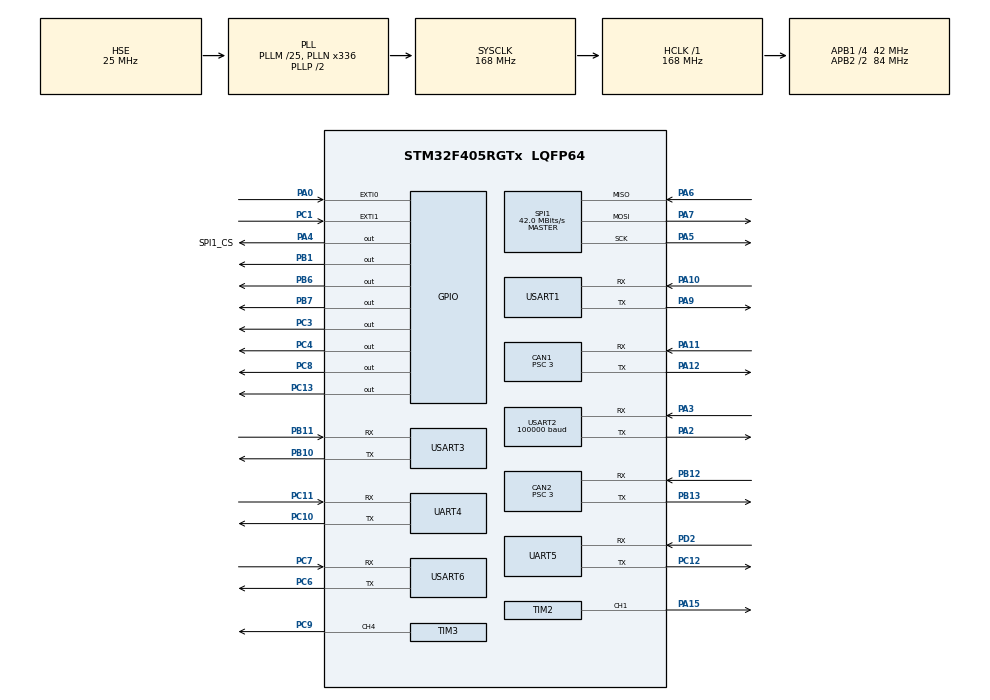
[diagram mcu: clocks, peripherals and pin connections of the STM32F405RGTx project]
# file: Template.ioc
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CAN1.ABOM=ENABLE
CAN1.BS1=CAN_BS1_9TQ
CAN1.BS2=CAN_BS2_4TQ
CAN1.CalculateBaudRate=1000000
CAN1.CalculateTimeBit=1000
CAN1.CalculateTimeQuantum=71.42857142857143
CAN1.NART=ENABLE
CAN1.Prescaler=3
CAN2.ABOM=ENABLE
CAN2.BS1=CAN_BS1_9TQ
CAN2.BS2=CAN_BS2_4TQ
CAN2.CalculateBaudRate=1000000
CAN2.CalculateTimeBit=1000
CAN2.CalculateTimeQuantum=71.42857142857143
CAN2.NART=ENABLE
CAN2.Prescaler=3
Dma.Request0=UART4_RX
Dma.Request1=UART4_TX
Dma.Request10=USART2_RX
Dma.Request2=UART5_RX
Dma.Request3=UART5_TX
Dma.Request4=USART1_RX
Dma.Request5=USART1_TX
Dma.Request6=USART3_RX
Dma.Request7=USART3_TX
Dma.Request8=USART6_RX
Dma.Request9=USART6_TX
Dma.UART4_RX.0.Direction=DMA_PERIPH_TO_MEMORY
Dma.UART4_RX.0.FIFOMode=DMA_FIFOMODE_DISABLE
Dma.UART4_RX.0.Instance=DMA1_Stream2
Dma.UART4_RX.0.MemDataAlignment=DMA_MDATAALIGN_BYTE
Dma.UART4_RX.0.MemInc=DMA_MINC_ENABLE
Dma.UART4_RX.0.Mode=DMA_NORMAL
Dma.UART4_RX.0.PeriphDataAlignment=DMA_PDATAALIGN_BYTE
Dma.UART4_RX.0.PeriphInc=DMA_PINC_DISABLE
Dma.UART4_RX.0.Priority=DMA_PRIORITY_LOW
Dma.UART4_TX.1.Direction=DMA_MEMORY_TO_PERIPH
Dma.UART4_TX.1.FIFOMode=DMA_FIFOMODE_DISABLE
Dma.UART4_TX.1.Instance=DMA1_Stream4
Dma.UART4_TX.1.MemDataAlignment=DMA_MDATAALIGN_BYTE
Dma.UART4_TX.1.MemInc=DMA_MINC_ENABLE
Dma.UART4_TX.1.Mode=DMA_NORMAL
Dma.UART4_TX.1.PeriphDataAlignment=DMA_PDATAALIGN_BYTE
Dma.UART4_TX.1.PeriphInc=DMA_PINC_DISABLE
Dma.UART4_TX.1.Priority=DMA_PRIORITY_LOW
Dma.UART5_RX.2.Direction=DMA_PERIPH_TO_MEMORY
Dma.UART5_RX.2.FIFOMode=DMA_FIFOMODE_DISABLE
Dma.UART5_RX.2.Instance=DMA1_Stream0
Dma.UART5_RX.2.MemDataAlignment=DMA_MDATAALIGN_BYTE
Dma.UART5_RX.2.MemInc=DMA_MINC_ENABLE
Dma.UART5_RX.2.Mode=DMA_NORMAL
Dma.UART5_RX.2.PeriphDataAlignment=DMA_PDATAALIGN_BYTE
Dma.UART5_RX.2.PeriphInc=DMA_PINC_DISABLE
Dma.UART5_RX.2.Priority=DMA_PRIORITY_LOW
Dma.UART5_TX.3.Direction=DMA_MEMORY_TO_PERIPH
Dma.UART5_TX.3.FIFOMode=DMA_FIFOMODE_DISABLE
Dma.UART5_TX.3.Instance=DMA1_Stream7
Dma.UART5_TX.3.MemDataAlignment=DMA_MDATAALIGN_BYTE
Dma.UART5_TX.3.MemInc=DMA_MINC_ENABLE
Dma.UART5_TX.3.Mode=DMA_NORMAL
Dma.UART5_TX.3.PeriphDataAlignment=DMA_PDATAALIGN_BYTE
Dma.UART5_TX.3.PeriphInc=DMA_PINC_DISABLE
Dma.UART5_TX.3.Priority=DMA_PRIORITY_LOW
Dma.USART1_RX.4.Direction=DMA_PERIPH_TO_MEMORY
Dma.USART1_RX.4.FIFOMode=DMA_FIFOMODE_DISABLE
Dma.USART1_RX.4.Instance=DMA2_Stream2
Dma.USART1_RX.4.MemDataAlignment=DMA_MDATAALIGN_BYTE
Dma.USART1_RX.4.MemInc=DMA_MINC_ENABLE
Dma.USART1_RX.4.Mode=DMA_NORMAL
Dma.USART1_RX.4.PeriphDataAlignment=DMA_PDATAALIGN_BYTE
Dma.USART1_RX.4.PeriphInc=DMA_PINC_DISABLE
Dma.USART1_RX.4.Priority=DMA_PRIORITY_LOW
Dma.USART1_TX.5.Direction=DMA_MEMORY_TO_PERIPH
Dma.USART1_TX.5.FIFOMode=DMA_FIFOMODE_DISABLE
Dma.USART1_TX.5.Instance=DMA2_Stream7
Dma.USART1_TX.5.MemDataAlignment=DMA_MDATAALIGN_BYTE
Dma.USART1_TX.5.MemInc=DMA_MINC_ENABLE
Dma.USART1_TX.5.Mode=DMA_NORMAL
Dma.USART1_TX.5.PeriphDataAlignment=DMA_PDATAALIGN_BYTE
Dma.USART1_TX.5.PeriphInc=DMA_PINC_DISABLE
Dma.USART1_TX.5.Priority=DMA_PRIORITY_LOW
Dma.USART2_RX.10.Direction=DMA_PERIPH_TO_MEMORY
Dma.USART2_RX.10.FIFOMode=DMA_FIFOMODE_DISABLE
Dma.USART2_RX.10.Instance=DMA1_Stream5
Dma.USART2_RX.10.MemDataAlignment=DMA_MDATAALIGN_BYTE
Dma.USART2_RX.10.MemInc=DMA_MINC_ENABLE
Dma.USART2_RX.10.Mode=DMA_NORMAL
Dma.USART2_RX.10.PeriphDataAlignment=DMA_PDATAALIGN_BYTE
Dma.USART2_RX.10.PeriphInc=DMA_PINC_DISABLE
Dma.USART2_RX.10.Priority=DMA_PRIORITY_LOW
Dma.USART3_RX.6.Direction=DMA_PERIPH_TO_MEMORY
Dma.USART3_RX.6.FIFOMode=DMA_FIFOMODE_DISABLE
Dma.USART3_RX.6.Instance=DMA1_Stream1
Dma.USART3_RX.6.MemDataAlignment=DMA_MDATAALIGN_BYTE
Dma.USART3_RX.6.MemInc=DMA_MINC_ENABLE
Dma.USART3_RX.6.Mode=DMA_NORMAL
Dma.USART3_RX.6.PeriphDataAlignment=DMA_PDATAALIGN_BYTE
Dma.USART3_RX.6.PeriphInc=DMA_PINC_DISABLE
Dma.USART3_RX.6.Priority=DMA_PRIORITY_LOW
Dma.USART3_TX.7.Direction=DMA_MEMORY_TO_PERIPH
Dma.USART3_TX.7.FIFOMode=DMA_FIFOMODE_DISABLE
Dma.USART3_TX.7.Instance=DMA1_Stream3
Dma.USART3_TX.7.MemDataAlignment=DMA_MDATAALIGN_BYTE
Dma.USART3_TX.7.MemInc=DMA_MINC_ENABLE
Dma.USART3_TX.7.Mode=DMA_NORMAL
Dma.USART3_TX.7.PeriphDataAlignment=DMA_PDATAALIGN_BYTE
Dma.USART3_TX.7.PeriphInc=DMA_PINC_DISABLE
Dma.USART3_TX.7.Priority=DMA_PRIORITY_LOW
Dma.USART6_RX.8.Direction=DMA_PERIPH_TO_MEMORY
Dma.USART6_RX.8.FIFOMode=DMA_FIFOMODE_DISABLE
Dma.USART6_RX.8.Instance=DMA2_Stream1
Dma.USART6_RX.8.MemDataAlignment=DMA_MDATAALIGN_BYTE
Dma.USART6_RX.8.MemInc=DMA_MINC_ENABLE
Dma.USART6_RX.8.Mode=DMA_NORMAL
Dma.USART6_RX.8.PeriphDataAlignment=DMA_PDATAALIGN_BYTE
Dma.USART6_RX.8.PeriphInc=DMA_PINC_DISABLE
Dma.USART6_RX.8.Priority=DMA_PRIORITY_LOW
Dma.USART6_TX.9.Direction=DMA_MEMORY_TO_PERIPH
Dma.USART6_TX.9.FIFOMode=DMA_FIFOMODE_DISABLE
Dma.USART6_TX.9.Instance=DMA2_Stream6
Dma.USART6_TX.9.MemDataAlignment=DMA_MDATAALIGN_BYTE
Dma.USART6_TX.9.MemInc=DMA_MINC_ENABLE
Dma.USART6_TX.9.Mode=DMA_NORMAL
Dma.USART6_TX.9.PeriphDataAlignment=DMA_PDATAALIGN_BYTE
Dma.USART6_TX.9.PeriphInc=DMA_PINC_DISABLE
Dma.USART6_TX.9.Priority=DMA_PRIORITY_LOW
FREERTOS.INCLUDE_vTaskDelayUntil=1
FREERTOS.Tasks01=defaultTask,0,128,StartDefaultTask,Default,NULL
Mcu.Family=STM32F4
Mcu.Name=STM32F405RGTx
Mcu.Package=LQFP64
NVIC.CAN1_RX0_IRQn=true\:5\:0\:false\:false\:true\:true\:true\:true\:true
NVIC.CAN1_RX1_IRQn=true\:5\:0\:false\:false\:true\:true\:true\:true\:true
NVIC.CAN2_RX0_IRQn=true\:5\:0\:false\:false\:true\:true\:true\:true\:true
NVIC.CAN2_RX1_IRQn=true\:5\:0\:false\:false\:true\:true\:true\:true\:true
NVIC.DMA1_Stream0_IRQn=true\:5\:0\:false\:false\:true\:true\:false\:true\:true
NVIC.DMA1_Stream1_IRQn=true\:5\:0\:false\:false\:true\:true\:false\:true\:true
NVIC.DMA1_Stream2_IRQn=true\:5\:0\:false\:false\:true\:true\:false\:true\:true
NVIC.DMA1_Stream3_IRQn=true\:5\:0\:false\:false\:true\:true\:false\:true\:true
NVIC.DMA1_Stream4_IRQn=true\:5\:0\:false\:false\:true\:true\:false\:true\:true
NVIC.DMA1_Stream5_IRQn=true\:5\:0\:false\:false\:true\:true\:false\:true\:true
NVIC.DMA1_Stream7_IRQn=true\:5\:0\:false\:false\:true\:true\:false\:true\:true
NVIC.DMA2_Stream1_IRQn=true\:5\:0\:false\:false\:true\:true\:false\:true\:true
NVIC.DMA2_Stream2_IRQn=true\:5\:0\:false\:false\:true\:true\:false\:true\:true
NVIC.DMA2_Stream6_IRQn=true\:5\:0\:false\:false\:true\:true\:false\:true\:true
NVIC.DMA2_Stream7_IRQn=true\:5\:0\:false\:false\:true\:true\:false\:true\:true
NVIC.EXTI0_IRQn=true\:5\:0\:false\:false\:true\:false\:true\:true\:true
NVIC.EXTI1_IRQn=true\:5\:0\:false\:false\:true\:false\:true\:true\:true
NVIC.PriorityGroup=NVIC_PRIORITYGROUP_4
NVIC.TIM4_IRQn=true\:5\:0\:false\:false\:true\:false\:true\:true\:true
NVIC.TIM7_IRQn=true\:0\:0\:false\:false\:true\:false\:false\:true\:true
NVIC.TimeBase=TIM7_IRQn
NVIC.TimeBaseIP=TIM7
NVIC.UART4_IRQn=true\:5\:0\:false\:false\:true\:true\:true\:true\:true
NVIC.UART5_IRQn=true\:5\:0\:false\:false\:true\:true\:true\:true\:true
NVIC.USART1_IRQn=true\:5\:0\:false\:false\:true\:true\:true\:true\:true
NVIC.USART2_IRQn=true\:5\:0\:false\:false\:true\:true\:true\:true\:true
NVIC.USART3_IRQn=true\:5\:0\:false\:false\:true\:true\:true\:true\:true
NVIC.USART6_IRQn=true\:5\:0\:false\:false\:true\:true\:true\:true\:true
PA0-WKUP.GPIO_PuPd=GPIO_PULLUP
PA0-WKUP.Signal=GPXTI0
PA10.Mode=Asynchronous
PA10.Signal=USART1_RX
PA11.Mode=CAN_Activate
PA11.Signal=CAN1_RX
PA12.Mode=CAN_Activate
PA12.Signal=CAN1_TX
PA13.Mode=Serial_Wire
PA13.Signal=SYS_JTMS-SWDIO
PA14.Mode=Serial_Wire
PA14.Signal=SYS_JTCK-SWCLK
PA15.Signal=S_TIM2_CH1_ETR
PA2.Mode=Asynchronous
PA2.Signal=USART2_TX
PA3.Mode=Asynchronous
PA3.Signal=USART2_RX
PA4.GPIO_Label=SPI1_CS
PA4.GPIO_Speed=GPIO_SPEED_FREQ_HIGH
PA4.Signal=GPIO_Output
PA5.Mode=Full_Duplex_Master
PA5.Signal=SPI1_SCK
PA6.Mode=Full_Duplex_Master
PA6.Signal=SPI1_MISO
PA7.Mode=Full_Duplex_Master
PA7.Signal=SPI1_MOSI
PA9.Mode=Asynchronous
PA9.Signal=USART1_TX
PB1.Signal=GPIO_Output
PB10.Mode=Asynchronous
PB10.Signal=USART3_TX
PB11.Mode=Asynchronous
PB11.Signal=USART3_RX
PB12.Mode=CAN_Activate
PB12.Signal=CAN2_RX
PB13.Mode=CAN_Activate
PB13.Signal=CAN2_TX
PB6.GPIO_ModeDefaultOutputPP=GPIO_MODE_OUTPUT_OD
PB6.GPIO_PuPd=GPIO_PULLUP
PB6.GPIO_Speed=GPIO_SPEED_FREQ_VERY_HIGH
PB6.PinState=GPIO_PIN_RESET
PB6.Signal=GPIO_Output
PB7.GPIO_ModeDefaultOutputPP=GPIO_MODE_OUTPUT_OD
PB7.GPIO_PuPd=GPIO_PULLUP
PB7.GPIO_Speed=GPIO_SPEED_FREQ_VERY_HIGH
PB7.Signal=GPIO_Output
PC1.GPIO_PuPd=GPIO_PULLUP
PC1.Signal=GPXTI1
PC10.Mode=Asynchronous
PC10.Signal=UART4_TX
PC11.Mode=Asynchronous
PC11.Signal=UART4_RX
PC12.Mode=Asynchronous
PC12.Signal=UART5_TX
PC13-ANTI_TAMP.Signal=GPIO_Output
PC3.GPIO_PuPd=GPIO_PULLUP
PC3.Signal=GPIO_Output
PC4.Signal=GPIO_Output
PC6.Mode=Asynchronous
PC6.Signal=USART6_TX
PC7.Mode=Asynchronous
PC7.Signal=USART6_RX
PC8.Signal=GPIO_Output
PC9.Signal=S_TIM3_CH4
PD2.Mode=Asynchronous
PD2.Signal=UART5_RX
PH0-OSC_IN.Mode=HSE-External-Oscillator
PH0-OSC_IN.Signal=RCC_OSC_IN
PH1-OSC_OUT.Mode=HSE-External-Oscillator
PH1-OSC_OUT.Signal=RCC_OSC_OUT
ProjectManager.HeapSize=0x200
ProjectManager.StackSize=0x400
ProjectManager.TargetToolchain=MDK-ARM V5.27
RCC.48MHZClocksFreq_Value=84000000
RCC.AHBFreq_Value=168000000
RCC.APB1CLKDivider=RCC_HCLK_DIV4
RCC.APB1Freq_Value=42000000
RCC.APB1TimFreq_Value=84000000
RCC.APB2CLKDivider=RCC_HCLK_DIV2
RCC.APB2Freq_Value=84000000
RCC.APB2TimFreq_Value=168000000
RCC.CortexFreq_Value=168000000
RCC.HCLKFreq_Value=168000000
RCC.HSE_VALUE=25000000
RCC.HSI_VALUE=16000000
RCC.LSE_VALUE=32768
RCC.PLLM=25
RCC.PLLN=336
RCC.PLLSourceVirtual=RCC_PLLSOURCE_HSE
RCC.RCC_RTC_Clock_Source=RCC_RTCCLKSOURCE_LSI
RCC.RCC_RTC_Clock_SourceVirtual=RCC_RTCCLKSOURCE_LSI
RCC.SYSCLKFreq_VALUE=168000000
RCC.SYSCLKSource=RCC_SYSCLKSOURCE_PLLCLK
RCC.VCOOutputFreq_Value=336000000
SH.S_TIM2_CH1_ETR.0=TIM2_CH1,PWM Generation1 CH1
SH.S_TIM3_CH4.0=TIM3_CH4,PWM Generation4 CH4
SPI1.CalculateBaudRate=42.0 MBits/s
SPI1.Direction=SPI_DIRECTION_2LINES
SPI1.Mode=SPI_MODE_MASTER
SPI1.VirtualType=VM_MASTER
TIM2.Channel-PWM\ Generation1\ CH1=TIM_CHANNEL_1
TIM2.OCMode_PWM-PWM\ Generation1\ CH1=TIM_OCMODE_PWM2
TIM2.Period=999
TIM2.Prescaler=41
TIM3.Channel-PWM\ Generation4\ CH4=TIM_CHANNEL_4
TIM3.OCMode_PWM-PWM\ Generation4\ CH4=TIM_OCMODE_PWM2
TIM3.Period=999
TIM3.Prescaler=42
TIM4.Period=65535
TIM4.Prescaler=83
UART4.VirtualMode=Asynchronous
UART5.VirtualMode=Asynchronous
USART1.VirtualMode=VM_ASYNC
USART2.BaudRate=100000
USART2.Mode=MODE_RX
USART2.Parity=PARITY_EVEN
USART2.VirtualMode=VM_ASYNC
USART2.WordLength=WORDLENGTH_9B
USART3.VirtualMode=VM_ASYNC
USART6.VirtualMode=VM_ASYNC
VP_FREERTOS_VS_CMSIS_V1.Mode=CMSIS_V1
VP_SYS_VS_tim7.Mode=TIM7
VP_TIM2_VS_ClockSourceINT.Mode=Internal
VP_TIM3_VS_ClockSourceINT.Mode=Internal
VP_TIM4_VS_ClockSourceINT.Mode=Internal
board=custom

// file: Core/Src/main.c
/* USER CODE BEGIN Header */
/**
  ******************************************************************************
  * @file           : main.c
  * @brief          : Main program body
  ******************************************************************************
  * @attention
  *
  * <h2><center>&copy; Copyright (c) 2019 STMicroelectronics.
  * All rights reserved.</center></h2>
  *
  * This software component is licensed by ST under Ultimate Liberty license
  * SLA0044, the "License"; You may not use this file except in compliance with
  * the License. You may obtain a copy of the License at:
  *                             www.st.com/SLA0044
  *
  ******************************************************************************
  */
/* USER CODE END Header */
#include "main.h"
#include "cmsis_os.h"

/* USER CODE BEGIN Includes */
#include "app.h"
#include "SRML.h"
/* USER CODE END Includes */

CAN_HandleTypeDef hcan1;
CAN_HandleTypeDef hcan2;

SPI_HandleTypeDef hspi1;

TIM_HandleTypeDef htim2;
TIM_HandleTypeDef htim3;
TIM_HandleTypeDef htim4;

UART_HandleTypeDef huart4;
UART_HandleTypeDef huart5;
UART_HandleTypeDef huart1;
UART_HandleTypeDef huart2;
UART_HandleTypeDef huart3;
UART_HandleTypeDef huart6;
DMA_HandleTypeDef hdma_uart4_rx;
DMA_HandleTypeDef hdma_uart4_tx;
DMA_HandleTypeDef hdma_uart5_rx;
DMA_HandleTypeDef hdma_uart5_tx;
DMA_HandleTypeDef hdma_usart1_rx;
DMA_HandleTypeDef hdma_usart1_tx;
DMA_HandleTypeDef hdma_usart2_rx;
DMA_HandleTypeDef hdma_usart3_rx;
DMA_HandleTypeDef hdma_usart3_tx;
DMA_HandleTypeDef hdma_usart6_rx;
DMA_HandleTypeDef hdma_usart6_tx;

osThreadId defaultTaskHandle;

void SystemClock_Config(void);
static void MX_GPIO_Init(void);
static void MX_DMA_Init(void);
static void MX_CAN1_Init(void);
static void MX_CAN2_Init(void);
static void MX_TIM4_Init(void);
static void MX_UART4_Init(void);
static void MX_UART5_Init(void);
static void MX_USART1_UART_Init(void);
static void MX_USART2_UART_Init(void);
static void MX_USART3_UART_Init(void);
static void MX_USART6_UART_Init(void);
static void MX_SPI1_Init(void);
static void MX_TIM2_Init(void);
static void MX_TIM3_Init(void);
void StartDefaultTask(void const * argument);

int main(void)
{

  /* MCU Configuration--------------------------------------------------------*/

  /* Reset of all peripherals, Initializes the Flash interface and the Systick. */
  HAL_Init();

  /* Configure the system clock */
  SystemClock_Config();

  /* Initialize all configured peripherals */
  MX_GPIO_Init();
  MX_DMA_Init();
  MX_CAN1_Init();
  MX_CAN2_Init();
  MX_TIM4_Init();
  MX_UART4_Init();
  MX_UART5_Init();
  MX_USART1_UART_Init();
  MX_USART2_UART_Init();
  MX_USART3_UART_Init();
  MX_USART6_UART_Init();
  MX_SPI1_Init();
  MX_TIM2_Init();
  MX_TIM3_Init();
  /* USER CODE BEGIN 2 */
  System_Device_Init();
	HAL_TIM_PWM_Start(&htim2, TIM_CHANNEL_1);
	HAL_TIM_PWM_Start(&htim3, TIM_CHANNEL_4);
  /* USER CODE END 2 */

  /* Create the thread(s) */
  /* definition and creation of defaultTask */
  osThreadDef(defaultTask, StartDefaultTask, osPriorityNormal, 0, 128);
  defaultTaskHandle = osThreadCreate(osThread(defaultTask), NULL);

  /* Start scheduler */
  osKernelStart();
  /* We should never get here as control is now taken by the scheduler */
  /* Infinite loop */
  while (1)
  {

  }
}

void SystemClock_Config(void)
{
  RCC_OscInitTypeDef RCC_OscInitStruct = {0};
  RCC_ClkInitTypeDef RCC_ClkInitStruct = {0};

  /** Configure the main internal regulator output voltage
  */
  __HAL_RCC_PWR_CLK_ENABLE();
  __HAL_PWR_VOLTAGESCALING_CONFIG(PWR_REGULATOR_VOLTAGE_SCALE1);

  /** Initializes the RCC Oscillators according to the specified parameters
  * in the RCC_OscInitTypeDef structure.
  */
  RCC_OscInitStruct.OscillatorType = RCC_OSCILLATORTYPE_HSE;
  RCC_OscInitStruct.HSEState = RCC_HSE_ON;
  RCC_OscInitStruct.PLL.PLLState = RCC_PLL_ON;
  RCC_OscInitStruct.PLL.PLLSource = RCC_PLLSOURCE_HSE;
  RCC_OscInitStruct.PLL.PLLM = 25;
  RCC_OscInitStruct.PLL.PLLN = 336;
  RCC_OscInitStruct.PLL.PLLP = RCC_PLLP_DIV2;
  RCC_OscInitStruct.PLL.PLLQ = 4;
  if (HAL_RCC_OscConfig(&RCC_OscInitStruct) != HAL_OK)
  {
    Error_Handler();
  }

  /** Initializes the CPU, AHB and APB buses clocks
  */
  RCC_ClkInitStruct.ClockType = RCC_CLOCKTYPE_HCLK|RCC_CLOCKTYPE_SYSCLK
                              |RCC_CLOCKTYPE_PCLK1|RCC_CLOCKTYPE_PCLK2;
  RCC_ClkInitStruct.SYSCLKSource = RCC_SYSCLKSOURCE_PLLCLK;
  RCC_ClkInitStruct.AHBCLKDivider = RCC_SYSCLK_DIV1;
  RCC_ClkInitStruct.APB1CLKDivider = RCC_HCLK_DIV4;
  RCC_ClkInitStruct.APB2CLKDivider = RCC_HCLK_DIV2;

  if (HAL_RCC_ClockConfig(&RCC_ClkInitStruct, FLASH_LATENCY_5) != HAL_OK)
  {
    Error_Handler();
  }
}

static void MX_CAN1_Init(void)
{

  hcan1.Instance = CAN1;
  hcan1.Init.Prescaler = 3;
  hcan1.Init.Mode = CAN_MODE_NORMAL;
  hcan1.Init.SyncJumpWidth = CAN_SJW_1TQ;
  hcan1.Init.TimeSeg1 = CAN_BS1_9TQ;
  hcan1.Init.TimeSeg2 = CAN_BS2_4TQ;
  hcan1.Init.TimeTriggeredMode = DISABLE;
  hcan1.Init.AutoBusOff = ENABLE;
  hcan1.Init.AutoWakeUp = DISABLE;
  hcan1.Init.AutoRetransmission = ENABLE;
  hcan1.Init.ReceiveFifoLocked = DISABLE;
  hcan1.Init.TransmitFifoPriority = DISABLE;
  if (HAL_CAN_Init(&hcan1) != HAL_OK)
  {
    Error_Handler();
  }

}

static void MX_CAN2_Init(void)
{

  hcan2.Instance = CAN2;
  hcan2.Init.Prescaler = 3;
  hcan2.Init.Mode = CAN_MODE_NORMAL;
  hcan2.Init.SyncJumpWidth = CAN_SJW_1TQ;
  hcan2.Init.TimeSeg1 = CAN_BS1_9TQ;
  hcan2.Init.TimeSeg2 = CAN_BS2_4TQ;
  hcan2.Init.TimeTriggeredMode = DISABLE;
  hcan2.Init.AutoBusOff = ENABLE;
  hcan2.Init.AutoWakeUp = DISABLE;
  hcan2.Init.AutoRetransmission = ENABLE;
  hcan2.Init.ReceiveFifoLocked = DISABLE;
  hcan2.Init.TransmitFifoPriority = DISABLE;
  if (HAL_CAN_Init(&hcan2) != HAL_OK)
  {
    Error_Handler();
  }

}

static void MX_SPI1_Init(void)
{

  /* SPI1 parameter configuration*/
  hspi1.Instance = SPI1;
  hspi1.Init.Mode = SPI_MODE_MASTER;
  hspi1.Init.Direction = SPI_DIRECTION_2LINES;
  hspi1.Init.DataSize = SPI_DATASIZE_8BIT;
  hspi1.Init.CLKPolarity = SPI_POLARITY_LOW;
  hspi1.Init.CLKPhase = SPI_PHASE_1EDGE;
  hspi1.Init.NSS = SPI_NSS_SOFT;
  hspi1.Init.BaudRatePrescaler = SPI_BAUDRATEPRESCALER_2;
  hspi1.Init.FirstBit = SPI_FIRSTBIT_MSB;
  hspi1.Init.TIMode = SPI_TIMODE_DISABLE;
  hspi1.Init.CRCCalculation = SPI_CRCCALCULATION_DISABLE;
  hspi1.Init.CRCPolynomial = 10;
  if (HAL_SPI_Init(&hspi1) != HAL_OK)
  {
    Error_Handler();
  }

}

static void MX_TIM2_Init(void)
{

  TIM_ClockConfigTypeDef sClockSourceConfig = {0};
  TIM_MasterConfigTypeDef sMasterConfig = {0};
  TIM_OC_InitTypeDef sConfigOC = {0};

  htim2.Instance = TIM2;
  htim2.Init.Prescaler = 41;
  htim2.Init.CounterMode = TIM_COUNTERMODE_UP;
  htim2.Init.Period = 999;
  htim2.Init.ClockDivision = TIM_CLOCKDIVISION_DIV1;
  htim2.Init.AutoReloadPreload = TIM_AUTORELOAD_PRELOAD_DISABLE;
  if (HAL_TIM_Base_Init(&htim2) != HAL_OK)
  {
    Error_Handler();
  }
  sClockSourceConfig.ClockSource = TIM_CLOCKSOURCE_INTERNAL;
  if (HAL_TIM_ConfigClockSource(&htim2, &sClockSourceConfig) != HAL_OK)
  {
    Error_Handler();
  }
  if (HAL_TIM_PWM_Init(&htim2) != HAL_OK)
  {
    Error_Handler();
  }
  sMasterConfig.MasterOutputTrigger = TIM_TRGO_RESET;
  sMasterConfig.MasterSlaveMode = TIM_MASTERSLAVEMODE_DISABLE;
  if (HAL_TIMEx_MasterConfigSynchronization(&htim2, &sMasterConfig) != HAL_OK)
  {
    Error_Handler();
  }
  sConfigOC.OCMode = TIM_OCMODE_PWM2;
  sConfigOC.Pulse = 0;
  sConfigOC.OCPolarity = TIM_OCPOLARITY_HIGH;
  sConfigOC.OCFastMode = TIM_OCFAST_DISABLE;
  if (HAL_TIM_PWM_ConfigChannel(&htim2, &sConfigOC, TIM_CHANNEL_1) != HAL_OK)
  {
    Error_Handler();
  }
  HAL_TIM_MspPostInit(&htim2);

}

static void MX_TIM3_Init(void)
{

  TIM_ClockConfigTypeDef sClockSourceConfig = {0};
  TIM_MasterConfigTypeDef sMasterConfig = {0};
  TIM_OC_InitTypeDef sConfigOC = {0};

  htim3.Instance = TIM3;
  htim3.Init.Prescaler = 42;
  htim3.Init.CounterMode = TIM_COUNTERMODE_UP;
  htim3.Init.Period = 999;
  htim3.Init.ClockDivision = TIM_CLOCKDIVISION_DIV1;
  htim3.Init.AutoReloadPreload = TIM_AUTORELOAD_PRELOAD_DISABLE;
  if (HAL_TIM_Base_Init(&htim3) != HAL_OK)
  {
    Error_Handler();
  }
  sClockSourceConfig.ClockSource = TIM_CLOCKSOURCE_INTERNAL;
  if (HAL_TIM_ConfigClockSource(&htim3, &sClockSourceConfig) != HAL_OK)
  {
    Error_Handler();
  }
  if (HAL_TIM_PWM_Init(&htim3) != HAL_OK)
  {
    Error_Handler();
  }
  sMasterConfig.MasterOutputTrigger = TIM_TRGO_RESET;
  sMasterConfig.MasterSlaveMode = TIM_MASTERSLAVEMODE_DISABLE;
  if (HAL_TIMEx_MasterConfigSynchronization(&htim3, &sMasterConfig) != HAL_OK)
  {
    Error_Handler();
  }
  sConfigOC.OCMode = TIM_OCMODE_PWM2;
  sConfigOC.Pulse = 0;
  sConfigOC.OCPolarity = TIM_OCPOLARITY_HIGH;
  sConfigOC.OCFastMode = TIM_OCFAST_DISABLE;
  if (HAL_TIM_PWM_ConfigChannel(&htim3, &sConfigOC, TIM_CHANNEL_4) != HAL_OK)
  {
    Error_Handler();
  }
  HAL_TIM_MspPostInit(&htim3);

}

static void MX_TIM4_Init(void)
{

  TIM_ClockConfigTypeDef sClockSourceConfig = {0};
  TIM_MasterConfigTypeDef sMasterConfig = {0};

  htim4.Instance = TIM4;
  htim4.Init.Prescaler = 83;
  htim4.Init.CounterMode = TIM_COUNTERMODE_UP;
  htim4.Init.Period = 65535;
  htim4.Init.ClockDivision = TIM_CLOCKDIVISION_DIV1;
  htim4.Init.AutoReloadPreload = TIM_AUTORELOAD_PRELOAD_DISABLE;
  if (HAL_TIM_Base_Init(&htim4) != HAL_OK)
  {
    Error_Handler();
  }
  sClockSourceConfig.ClockSource = TIM_CLOCKSOURCE_INTERNAL;
  if (HAL_TIM_ConfigClockSource(&htim4, &sClockSourceConfig) != HAL_OK)
  {
    Error_Handler();
  }
  sMasterConfig.MasterOutputTrigger = TIM_TRGO_RESET;
  sMasterConfig.MasterSlaveMode = TIM_MASTERSLAVEMODE_DISABLE;
  if (HAL_TIMEx_MasterConfigSynchronization(&htim4, &sMasterConfig) != HAL_OK)
  {
    Error_Handler();
  }

}

static void MX_UART4_Init(void)
{

  huart4.Instance = UART4;
  huart4.Init.BaudRate = 115200;
  huart4.Init.WordLength = UART_WORDLENGTH_8B;
  huart4.Init.StopBits = UART_STOPBITS_1;
  huart4.Init.Parity = UART_PARITY_NONE;
  huart4.Init.Mode = UART_MODE_TX_RX;
  huart4.Init.HwFlowCtl = UART_HWCONTROL_NONE;
  huart4.Init.OverSampling = UART_OVERSAMPLING_16;
  if (HAL_UART_Init(&huart4) != HAL_OK)
  {
    Error_Handler();
  }

}

static void MX_UART5_Init(void)
{

  huart5.Instance = UART5;
  huart5.Init.BaudRate = 115200;
  huart5.Init.WordLength = UART_WORDLENGTH_8B;
  huart5.Init.StopBits = UART_STOPBITS_1;
  huart5.Init.Parity = UART_PARITY_NONE;
  huart5.Init.Mode = UART_MODE_TX_RX;
  huart5.Init.HwFlowCtl = UART_HWCONTROL_NONE;
  huart5.Init.OverSampling = UART_OVERSAMPLING_16;
  if (HAL_UART_Init(&huart5) != HAL_OK)
  {
    Error_Handler();
  }

}

static void MX_USART1_UART_Init(void)
{

  huart1.Instance = USART1;
  huart1.Init.BaudRate = 115200;
  huart1.Init.WordLength = UART_WORDLENGTH_8B;
  huart1.Init.StopBits = UART_STOPBITS_1;
  huart1.Init.Parity = UART_PARITY_NONE;
  huart1.Init.Mode = UART_MODE_TX_RX;
  huart1.Init.HwFlowCtl = UART_HWCONTROL_NONE;
  huart1.Init.OverSampling = UART_OVERSAMPLING_16;
  if (HAL_UART_Init(&huart1) != HAL_OK)
  {
    Error_Handler();
  }

}

static void MX_USART2_UART_Init(void)
{

  huart2.Instance = USART2;
  huart2.Init.BaudRate = 100000;
  huart2.Init.WordLength = UART_WORDLENGTH_9B;
  huart2.Init.StopBits = UART_STOPBITS_1;
  huart2.Init.Parity = UART_PARITY_EVEN;
  huart2.Init.Mode = UART_MODE_RX;
  huart2.Init.HwFlowCtl = UART_HWCONTROL_NONE;
  huart2.Init.OverSampling = UART_OVERSAMPLING_16;
  if (HAL_UART_Init(&huart2) != HAL_OK)
  {
    Error_Handler();
  }

}

static void MX_USART3_UART_Init(void)
{

  huart3.Instance = USART3;
  huart3.Init.BaudRate = 115200;
  huart3.Init.WordLength = UART_WORDLENGTH_8B;
  huart3.Init.StopBits = UART_STOPBITS_1;
  huart3.Init.Parity = UART_PARITY_NONE;
  huart3.Init.Mode = UART_MODE_TX_RX;
  huart3.Init.HwFlowCtl = UART_HWCONTROL_NONE;
  huart3.Init.OverSampling = UART_OVERSAMPLING_16;
  if (HAL_UART_Init(&huart3) != HAL_OK)
  {
    Error_Handler();
  }

}

static void MX_USART6_UART_Init(void)
{

  huart6.Instance = USART6;
  huart6.Init.BaudRate = 115200;
  huart6.Init.WordLength = UART_WORDLENGTH_8B;
  huart6.Init.StopBits = UART_STOPBITS_1;
  huart6.Init.Parity = UART_PARITY_NONE;
  huart6.Init.Mode = UART_MODE_TX_RX;
  huart6.Init.HwFlowCtl = UART_HWCONTROL_NONE;
  huart6.Init.OverSampling = UART_OVERSAMPLING_16;
  if (HAL_UART_Init(&huart6) != HAL_OK)
  {
    Error_Handler();
  }

}

static void MX_DMA_Init(void)
{

  /* DMA controller clock enable */
  __HAL_RCC_DMA1_CLK_ENABLE();
  __HAL_RCC_DMA2_CLK_ENABLE();

  /* DMA interrupt init */
  /* DMA1_Stream0_IRQn interrupt configuration */
  HAL_NVIC_SetPriority(DMA1_Stream0_IRQn, 5, 0);
  HAL_NVIC_EnableIRQ(DMA1_Stream0_IRQn);
  /* DMA1_Stream1_IRQn interrupt configuration */
  HAL_NVIC_SetPriority(DMA1_Stream1_IRQn, 5, 0);
  HAL_NVIC_EnableIRQ(DMA1_Stream1_IRQn);
  /* DMA1_Stream2_IRQn interrupt configuration */
  HAL_NVIC_SetPriority(DMA1_Stream2_IRQn, 5, 0);
  HAL_NVIC_EnableIRQ(DMA1_Stream2_IRQn);
  /* DMA1_Stream3_IRQn interrupt configuration */
  HAL_NVIC_SetPriority(DMA1_Stream3_IRQn, 5, 0);
  HAL_NVIC_EnableIRQ(DMA1_Stream3_IRQn);
  /* DMA1_Stream4_IRQn interrupt configuration */
  HAL_NVIC_SetPriority(DMA1_Stream4_IRQn, 5, 0);
  HAL_NVIC_EnableIRQ(DMA1_Stream4_IRQn);
  /* DMA1_Stream5_IRQn interrupt configuration */
  HAL_NVIC_SetPriority(DMA1_Stream5_IRQn, 5, 0);
  HAL_NVIC_EnableIRQ(DMA1_Stream5_IRQn);
  /* DMA1_Stream7_IRQn interrupt configuration */
  HAL_NVIC_SetPriority(DMA1_Stream7_IRQn, 5, 0);
  HAL_NVIC_EnableIRQ(DMA1_Stream7_IRQn);
  /* DMA2_Stream1_IRQn interrupt configuration */
  HAL_NVIC_SetPriority(DMA2_Stream1_IRQn, 5, 0);
  HAL_NVIC_EnableIRQ(DMA2_Stream1_IRQn);
  /* DMA2_Stream2_IRQn interrupt configuration */
  HAL_NVIC_SetPriority(DMA2_Stream2_IRQn, 5, 0);
  HAL_NVIC_EnableIRQ(DMA2_Stream2_IRQn);
  /* DMA2_Stream6_IRQn interrupt configuration */
  HAL_NVIC_SetPriority(DMA2_Stream6_IRQn, 5, 0);
  HAL_NVIC_EnableIRQ(DMA2_Stream6_IRQn);
  /* DMA2_Stream7_IRQn interrupt configuration */
  HAL_NVIC_SetPriority(DMA2_Stream7_IRQn, 5, 0);
  HAL_NVIC_EnableIRQ(DMA2_Stream7_IRQn);

}

static void MX_GPIO_Init(void)
{
  GPIO_InitTypeDef GPIO_InitStruct = {0};

  /* GPIO Ports Clock Enable */
  __HAL_RCC_GPIOC_CLK_ENABLE();
  __HAL_RCC_GPIOH_CLK_ENABLE();
  __HAL_RCC_GPIOA_CLK_ENABLE();
  __HAL_RCC_GPIOB_CLK_ENABLE();
  __HAL_RCC_GPIOD_CLK_ENABLE();

  /*Configure GPIO pin Output Level */
  HAL_GPIO_WritePin(GPIOC, GPIO_PIN_13|GPIO_PIN_3|GPIO_PIN_4|GPIO_PIN_8, GPIO_PIN_RESET);

  /*Configure GPIO pin Output Level */
  HAL_GPIO_WritePin(SPI1_CS_GPIO_Port, SPI1_CS_Pin, GPIO_PIN_RESET);

  /*Configure GPIO pin Output Level */
  HAL_GPIO_WritePin(GPIOB, GPIO_PIN_1|GPIO_PIN_6|GPIO_PIN_7, GPIO_PIN_RESET);

  /*Configure GPIO pins : PC13 PC4 PC8 */
  GPIO_InitStruct.Pin = GPIO_PIN_13|GPIO_PIN_4|GPIO_PIN_8;
  GPIO_InitStruct.Mode = GPIO_MODE_OUTPUT_PP;
  GPIO_InitStruct.Pull = GPIO_NOPULL;
  GPIO_InitStruct.Speed = GPIO_SPEED_FREQ_LOW;
  HAL_GPIO_Init(GPIOC, &GPIO_InitStruct);

  /*Configure GPIO pin : PC1 */
  GPIO_InitStruct.Pin = GPIO_PIN_1;
  GPIO_InitStruct.Mode = GPIO_MODE_IT_RISING;
  GPIO_InitStruct.Pull = GPIO_PULLUP;
  HAL_GPIO_Init(GPIOC, &GPIO_InitStruct);

  /*Configure GPIO pin : PC3 */
  GPIO_InitStruct.Pin = GPIO_PIN_3;
  GPIO_InitStruct.Mode = GPIO_MODE_OUTPUT_PP;
  GPIO_InitStruct.Pull = GPIO_PULLUP;
  GPIO_InitStruct.Speed = GPIO_SPEED_FREQ_LOW;
  HAL_GPIO_Init(GPIOC, &GPIO_InitStruct);

  /*Configure GPIO pin : PA0 */
  GPIO_InitStruct.Pin = GPIO_PIN_0;
  GPIO_InitStruct.Mode = GPIO_MODE_IT_RISING;
  GPIO_InitStruct.Pull = GPIO_PULLUP;
  HAL_GPIO_Init(GPIOA, &GPIO_InitStruct);

  /*Configure GPIO pin : SPI1_CS_Pin */
  GPIO_InitStruct.Pin = SPI1_CS_Pin;
  GPIO_InitStruct.Mode = GPIO_MODE_OUTPUT_PP;
  GPIO_InitStruct.Pull = GPIO_NOPULL;
  GPIO_InitStruct.Speed = GPIO_SPEED_FREQ_HIGH;
  HAL_GPIO_Init(SPI1_CS_GPIO_Port, &GPIO_InitStruct);

  /*Configure GPIO pin : PB1 */
  GPIO_InitStruct.Pin = GPIO_PIN_1;
  GPIO_InitStruct.Mode = GPIO_MODE_OUTPUT_PP;
  GPIO_InitStruct.Pull = GPIO_NOPULL;
  GPIO_InitStruct.Speed = GPIO_SPEED_FREQ_LOW;
  HAL_GPIO_Init(GPIOB, &GPIO_InitStruct);

  /*Configure GPIO pins : PB6 PB7 */
  GPIO_InitStruct.Pin = GPIO_PIN_6|GPIO_PIN_7;
  GPIO_InitStruct.Mode = GPIO_MODE_OUTPUT_OD;
  GPIO_InitStruct.Pull = GPIO_PULLUP;
  GPIO_InitStruct.Speed = GPIO_SPEED_FREQ_VERY_HIGH;
  HAL_GPIO_Init(GPIOB, &GPIO_InitStruct);

  /* EXTI interrupt init*/
  HAL_NVIC_SetPriority(EXTI0_IRQn, 5, 0);
  HAL_NVIC_EnableIRQ(EXTI0_IRQn);

  HAL_NVIC_SetPriority(EXTI1_IRQn, 5, 0);
  HAL_NVIC_EnableIRQ(EXTI1_IRQn);

}

void StartDefaultTask(void const * argument)
{
  /* USER CODE BEGIN 5 */
	System_Task_Init();
  /* Delete the default task. */
  osThreadTerminate (defaultTaskHandle);
  /* Infinite loop */
  for(;;)
  {
	  osDelay(1);
  }
  /* USER CODE END 5 */
}

void HAL_TIM_PeriodElapsedCallback(TIM_HandleTypeDef *htim)
{
  /* USER CODE BEGIN Callback 0 */
  if (htim->Instance == TIM4) {
    Update_SystemTick();
  }
  /* USER CODE END Callback 0 */
  if (htim->Instance == TIM7) {
    HAL_IncTick();
  }
}

void Error_Handler(void)
{
}

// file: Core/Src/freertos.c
/* USER CODE BEGIN Header */
/**
  ******************************************************************************
  * File Name          : freertos.c
  * Description        : Code for freertos applications
  ******************************************************************************
  * @attention
  *
  * <h2><center>&copy; Copyright (c) 2019 STMicroelectronics.
  * All rights reserved.</center></h2>
  *
  * This software component is licensed by ST under Ultimate Liberty license
  * SLA0044, the "License"; You may not use this file except in compliance with
  * the License. You may obtain a copy of the License at:
  *                             www.st.com/SLA0044
  *
  ******************************************************************************
  */
/* USER CODE END Header */

#include "FreeRTOS.h"
#include "task.h"
#include "main.h"

/* GetIdleTaskMemory prototype (linked to static allocation support) */
void vApplicationGetIdleTaskMemory( StaticTask_t **ppxIdleTaskTCBBuffer, StackType_t **ppxIdleTaskStackBuffer, uint32_t *pulIdleTaskStackSize );

/* USER CODE BEGIN GET_IDLE_TASK_MEMORY */
static StaticTask_t xIdleTaskTCBBuffer;
static StackType_t xIdleStack[configMINIMAL_STACK_SIZE];

void vApplicationGetIdleTaskMemory( StaticTask_t **ppxIdleTaskTCBBuffer, StackType_t **ppxIdleTaskStackBuffer, uint32_t *pulIdleTaskStackSize )
{
  *ppxIdleTaskTCBBuffer = &xIdleTaskTCBBuffer;
  *ppxIdleTaskStackBuffer = &xIdleStack[0];
  *pulIdleTaskStackSize = configMINIMAL_STACK_SIZE;
  /* place for user code */
}
/* USER CODE END GET_IDLE_TASK_MEMORY */
